VERSION ""

NS_ :

BS_:

BU_:

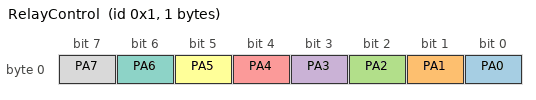
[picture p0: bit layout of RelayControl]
BO_ 1 RelayControl: 1 Vector__XXX
	SG_ PA0 : 0|1@1+ (1,0) [0|1] "" Vector__XXX
	SG_ PA1 : 1|1@1+ (1,0) [0|1] "" Vector__XXX
	SG_ PA2 : 2|1@1+ (1,0) [0|1] "" Vector__XXX
	SG_ PA3 : 3|1@1+ (1,0) [0|1] "" Vector__XXX
	SG_ PA4 : 4|1@1+ (1,0) [0|1] "" Vector__XXX
	SG_ PA5 : 5|1@1+ (1,0) [0|1] "" Vector__XXX
	SG_ PA6 : 6|1@1+ (1,0) [0|1] "" Vector__XXX
	SG_ PA7 : 7|1@1+ (1,0) [0|1] "" Vector__XXX

BA_DEF_ BO_ "GenMsgSendType" ENUM "cyclic","triggered","cyclicIfActive","cyclicAndTriggered","cyclicIfActiveAndTriggered","none";
BA_DEF_ BO_ "GenMsgCycleTime" INT 0 10000;
BA_DEF_ BO_ "GenMsgStartDelayTime" INT 0 10000;
BA_DEF_ BO_ "GenMsgILSupport" ENUM "No","Yes";

BA_DEF_DEF_ "GenMsgSendType" "none";
BA_DEF_DEF_ "GenMsgILSupport" "No";

BA_ "GenMsgSendType" BO_ 1 "cyclic";
BA_ "GenMsgCycleTime" BO_ 1 1;
BA_ "GenMsgStartDelayTime" BO_ 1 1000;
BA_ "GenMsgILSupport" BO_ 256 "Yes";

BA_DEF_ BO_  "VFrameFormat" ENUM  "StandardCAN","ExtendedCAN","reserved","J1939PG";
BA_DEF_DEF_  "VFrameFormat" "StandardCAN";
